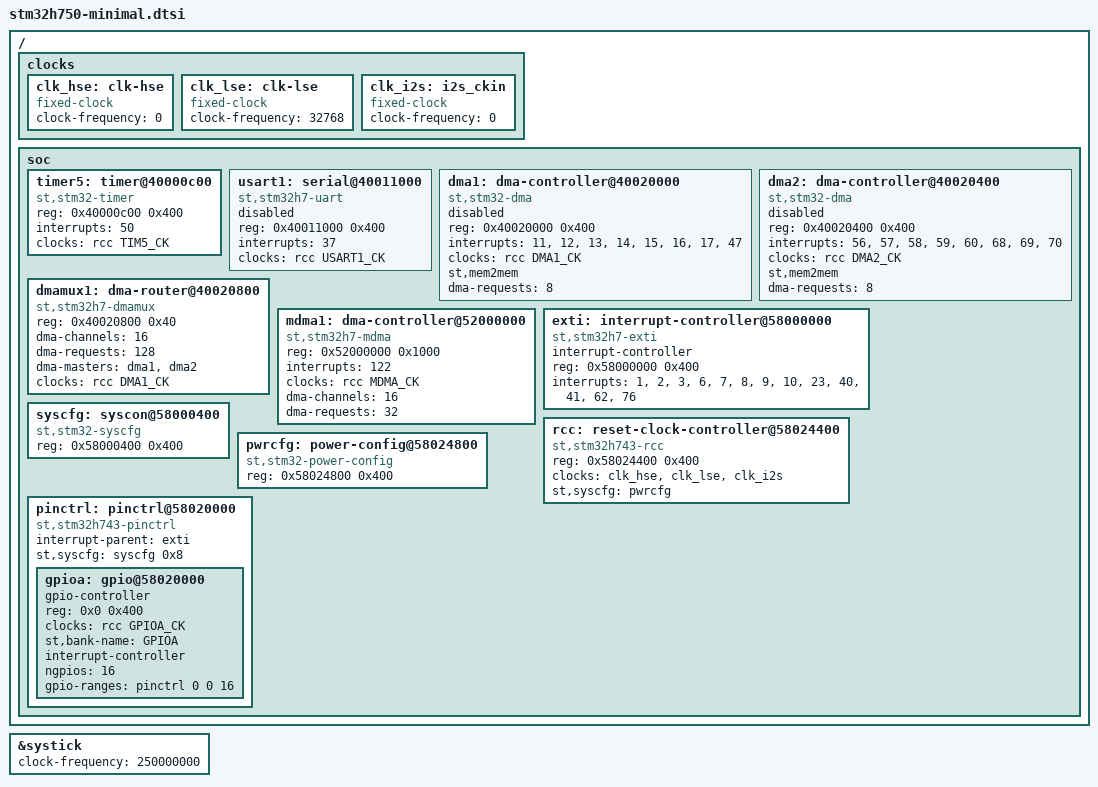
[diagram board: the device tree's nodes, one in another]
/*
 * Copyright 2017 - Alexandre Torgue <alexandre.torgue@st.com>
 *
 * This file is dual-licensed: you can use it either under the terms
 * of the GPL or the X11 license, at your option. Note that this dual
 * licensing only applies to this file, and not this project as a
 * whole.
 *
 *  a) This file is free software; you can redistribute it and/or
 *     modify it under the terms of the GNU General Public License as
 *     published by the Free Software Foundation; either version 2 of the
 *     License, or (at your option) any later version.
 *
 *     This file is distributed in the hope that it will be useful,
 *     but WITHOUT ANY WARRANTY; without even the implied warranty of
 *     MERCHANTABILITY or FITNESS FOR A PARTICULAR PURPOSE.  See the
 *     GNU General Public License for more details.
 *
 * Or, alternatively,
 *
 *  b) Permission is hereby granted, free of charge, to any person
 *     obtaining a copy of this software and associated documentation
 *     files (the "Software"), to deal in the Software without
 *     restriction, including without limitation the rights to use,
 *     copy, modify, merge, publish, distribute, sublicense, and/or
 *     sell copies of the Software, and to permit persons to whom the
 *     Software is furnished to do so, subject to the following
 *     conditions:
 *
 *     The above copyright notice and this permission notice shall be
 *     included in all copies or substantial portions of the Software.
 *
 *     THE SOFTWARE IS PROVIDED "AS IS", WITHOUT WARRANTY OF ANY KIND,
 *     EXPRESS OR IMPLIED, INCLUDING BUT NOT LIMITED TO THE WARRANTIES
 *     OF MERCHANTABILITY, FITNESS FOR A PARTICULAR PURPOSE AND
 *     NONINFRINGEMENT. IN NO EVENT SHALL THE AUTHORS OR COPYRIGHT
 *     HOLDERS BE LIABLE FOR ANY CLAIM, DAMAGES OR OTHER LIABILITY,
 *     WHETHER IN AN ACTION OF CONTRACT, TORT OR OTHERWISE, ARISING
 *     FROM, OUT OF OR IN CONNECTION WITH THE SOFTWARE OR THE USE OR
 *     OTHER DEALINGS IN THE SOFTWARE.
 */

#include "../armv7-m.dtsi"
#include <dt-bindings/clock/stm32h7-clks.h>
#include <dt-bindings/mfd/stm32h7-rcc.h>
#include <dt-bindings/interrupt-controller/irq.h>

/ {
	#address-cells = <1>;
	#size-cells = <1>;

	clocks {
		clk_hse: clk-hse {
			#clock-cells = <0>;
			compatible = "fixed-clock";
			clock-frequency = <0>;
		};

		clk_lse: clk-lse {
			#clock-cells = <0>;
			compatible = "fixed-clock";
			clock-frequency = <32768>;
		};

		clk_i2s: i2s_ckin {
			#clock-cells = <0>;
			compatible = "fixed-clock";
			clock-frequency = <0>;
		};
	};

	soc {
		timer5: timer@40000c00 {
			compatible = "st,stm32-timer";
			reg = <0x40000c00 0x400>;
			interrupts = <50>;
			clocks = <&rcc TIM5_CK>;
		};

		usart1: serial@40011000 {
			compatible = "st,stm32h7-uart";
			reg = <0x40011000 0x400>;
			interrupts = <37>;
			status = "disabled";
			clocks = <&rcc USART1_CK>;
		};


		dma1: dma-controller@40020000 {
			compatible = "st,stm32-dma";
			reg = <0x40020000 0x400>;
			interrupts = <11>,
				     <12>,
				     <13>,
				     <14>,
				     <15>,
				     <16>,
				     <17>,
				     <47>;
			clocks = <&rcc DMA1_CK>;
			#dma-cells = <4>;
			st,mem2mem;
			dma-requests = <8>;
			status = "disabled";
		};

		dma2: dma-controller@40020400 {
			compatible = "st,stm32-dma";
			reg = <0x40020400 0x400>;
			interrupts = <56>,
				     <57>,
				     <58>,
				     <59>,
				     <60>,
				     <68>,
				     <69>,
				     <70>;
			clocks = <&rcc DMA2_CK>;
			#dma-cells = <4>;
			st,mem2mem;
			dma-requests = <8>;
			status = "disabled";
		};

		dmamux1: dma-router@40020800 {
			compatible = "st,stm32h7-dmamux";
			reg = <0x40020800 0x40>;
			#dma-cells = <3>;
			dma-channels = <16>;
			dma-requests = <128>;
			dma-masters = <&dma1 &dma2>;
			clocks = <&rcc DMA1_CK>;
		};


		mdma1: dma-controller@52000000 {
			compatible = "st,stm32h7-mdma";
			reg = <0x52000000 0x1000>;
			interrupts = <122>;
			clocks = <&rcc MDMA_CK>;
			#dma-cells = <5>;
			dma-channels = <16>;
			dma-requests = <32>;
		};

		exti: interrupt-controller@58000000 {
			compatible = "st,stm32h7-exti";
			interrupt-controller;
			#interrupt-cells = <2>;
			reg = <0x58000000 0x400>;
			interrupts = <1>, <2>, <3>, <6>, <7>, <8>, <9>, <10>, <23>, <40>, <41>, <62>, <76>;
		};

		syscfg: syscon@58000400 {
			compatible = "st,stm32-syscfg", "syscon";
			reg = <0x58000400 0x400>;
		};

		rcc: reset-clock-controller@58024400 {
			compatible = "st,stm32h743-rcc", "st,stm32-rcc";
			reg = <0x58024400 0x400>;
			#clock-cells = <1>;
			#reset-cells = <1>;
			clocks = <&clk_hse>, <&clk_lse>, <&clk_i2s>;
			st,syscfg = <&pwrcfg>;
		};

		pwrcfg: power-config@58024800 {
			compatible = "st,stm32-power-config", "syscon";
			reg = <0x58024800 0x400>;
		};


		pinctrl: pinctrl@58020000 {
			#address-cells = <1>;
			#size-cells = <1>;
			compatible = "st,stm32h743-pinctrl";
			ranges = <0 0x58020000 0x3000>;
			interrupt-parent = <&exti>;
			st,syscfg = <&syscfg 0x8>;

			gpioa: gpio@58020000 {
				gpio-controller;
				#gpio-cells = <2>;
				reg = <0x0 0x400>;
				clocks = <&rcc GPIOA_CK>;
				st,bank-name = "GPIOA";
				interrupt-controller;
				#interrupt-cells = <2>;
				ngpios = <16>;
				gpio-ranges = <&pinctrl 0 0 16>;
			};
		};
	};
};

&systick {
	clock-frequency = <250000000>;
	status = "okay";
};
